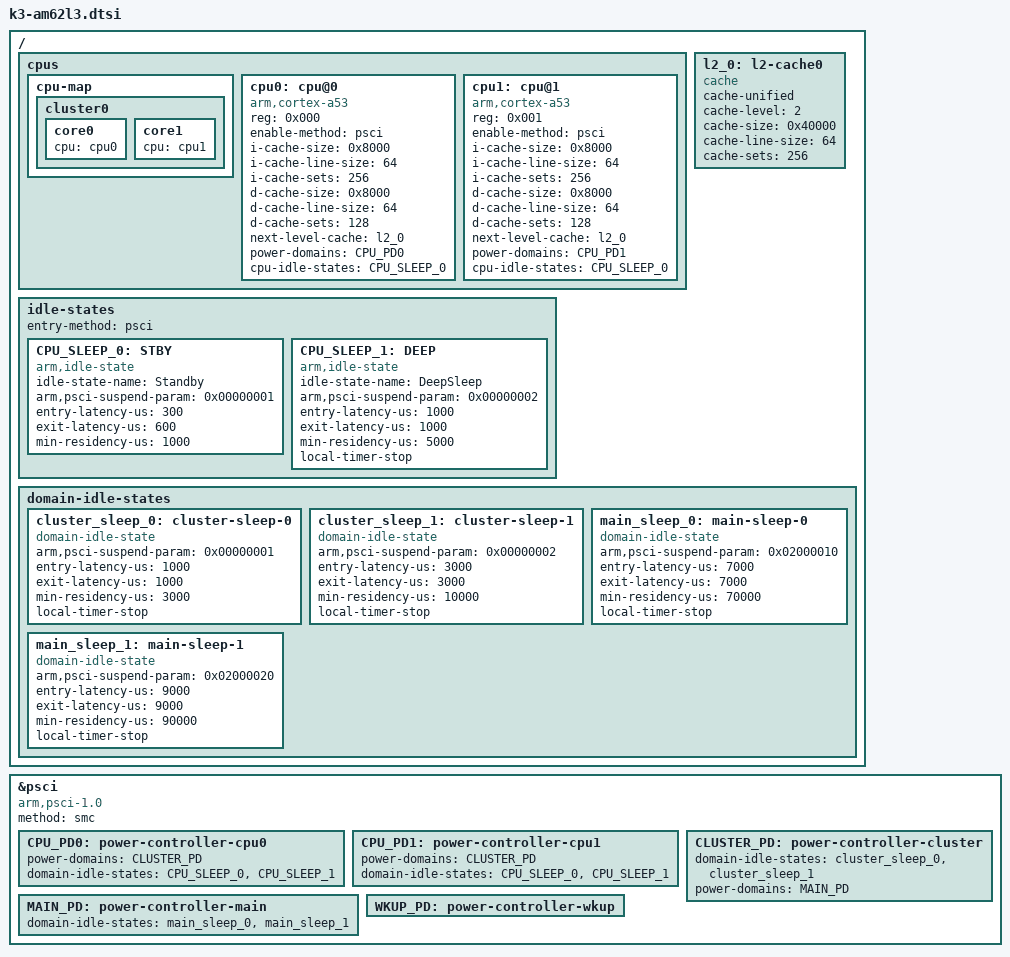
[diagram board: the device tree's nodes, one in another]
// SPDX-License-Identifier: GPL-2.0-only or MIT
/*
 * Device Tree file for the AM62L3 SoC family (Dual Core A53)
 * Copyright (C) 2024 Texas Instruments Incorporated - https://www.ti.com/
 *
 * Technical Reference Manual: https://www.ti.com/lit/pdf/sprujb4
 */

/dts-v1/;

#include "k3-am62l.dtsi"

/ {
	cpus {
		#address-cells = <1>;
		#size-cells = <0>;

		cpu-map {
			cluster0: cluster0 {
				core0 {
					cpu = <&cpu0>;
				};

				core1 {
					cpu = <&cpu1>;
				};
			};
		};

		cpu0: cpu@0 {
			compatible = "arm,cortex-a53";
			reg = <0x000>;
			device_type = "cpu";
			enable-method = "psci";
			i-cache-size = <0x8000>;
			i-cache-line-size = <64>;
			i-cache-sets = <256>;
			d-cache-size = <0x8000>;
			d-cache-line-size = <64>;
			d-cache-sets = <128>;
			next-level-cache = <&l2_0>;
			power-domains = <&CPU_PD0>;
			power-domain-names = "psci";
			cpu-idle-states = <&CPU_SLEEP_0>;
		};

		cpu1: cpu@1 {
			compatible = "arm,cortex-a53";
			reg = <0x001>;
			device_type = "cpu";
			enable-method = "psci";
			i-cache-size = <0x8000>;
			i-cache-line-size = <64>;
			i-cache-sets = <256>;
			d-cache-size = <0x8000>;
			d-cache-line-size = <64>;
			d-cache-sets = <128>;
			next-level-cache = <&l2_0>;
			power-domains = <&CPU_PD1>;
			power-domain-names = "psci";
			cpu-idle-states = <&CPU_SLEEP_0>;
		};
	};

	l2_0: l2-cache0 {
		compatible = "cache";
		cache-unified;
		cache-level = <2>;
		cache-size = <0x40000>;
		cache-line-size = <64>;
		cache-sets = <256>;
	};


	idle-states {
		entry-method = "psci";

		CPU_SLEEP_0: STBY {
			compatible = "arm,idle-state";
			idle-state-name = "Standby";
			arm,psci-suspend-param = <0x00000001>;
			entry-latency-us = <300>;
			exit-latency-us = <600>;
			min-residency-us = <1000>;
		};

		CPU_SLEEP_1: DEEP {
			compatible = "arm,idle-state";
			idle-state-name = "DeepSleep";
			arm,psci-suspend-param = <0x00000002>;
			entry-latency-us = <1000>;
			exit-latency-us = <1000>;
			min-residency-us = <5000>;
			local-timer-stop;
		};
	};

/*
 * psci-suspend-param bits:
 * From: PSCI spec, Table 7
 *
 * 31:26 - reserved, must be zero
 * 25:24 - PowerLevel: 0-core, 1-cluster, 2-system.
 * 23:17 - reserved, must be zero
 * 16    - StateType: 0-retention, 1-power-down (context loss)
 * 15:0  - StateID.
 */

	domain-idle-states {
		cluster_sleep_0: cluster-sleep-0 {
			compatible = "domain-idle-state";
			arm,psci-suspend-param = <0x00000001>; /* cluster state */
			entry-latency-us = <1000>;
			exit-latency-us = <1000>;
			min-residency-us = <3000>;
			local-timer-stop;
		};

		cluster_sleep_1: cluster-sleep-1 {
			compatible = "domain-idle-state";
			arm,psci-suspend-param = <0x00000002>; /* system state */
			entry-latency-us = <3000>;
			exit-latency-us = <3000>;
			min-residency-us = <10000>;
			local-timer-stop;
		};

		main_sleep_0: main-sleep-0 {
			compatible = "domain-idle-state";
			arm,psci-suspend-param = <0x02000010>; /* system state */
			entry-latency-us = <7000>;
			exit-latency-us = <7000>;
			min-residency-us = <70000>;
			local-timer-stop;
		};

		main_sleep_1: main-sleep-1 {
			compatible = "domain-idle-state";
			arm,psci-suspend-param = <0x02000020>; /* system state */
			entry-latency-us = <9000>;
			exit-latency-us = <9000>;
			min-residency-us = <90000>;
			local-timer-stop;
		};
	};
};

&psci {
	compatible = "arm,psci-1.0";
	method = "smc";

	CPU_PD0: power-controller-cpu0 {
		#power-domain-cells = <0>;
		power-domains = <&CLUSTER_PD>;
		domain-idle-states = <&CPU_SLEEP_0>, <&CPU_SLEEP_1>;
	};

	CPU_PD1: power-controller-cpu1 {
		#power-domain-cells = <0>;
		power-domains = <&CLUSTER_PD>;
		domain-idle-states = <&CPU_SLEEP_0>, <&CPU_SLEEP_1>;
	};

	CLUSTER_PD: power-controller-cluster {
		#power-domain-cells = <0>;
		domain-idle-states = <&cluster_sleep_0>, <&cluster_sleep_1>;
		power-domains = <&MAIN_PD>;
	};

	MAIN_PD: power-controller-main {
		#power-domain-cells = <0>;
		domain-idle-states = <&main_sleep_0>, <&main_sleep_1>;
	};

	WKUP_PD: power-controller-wkup {
		#power-domain-cells = <0>;
	};
};
